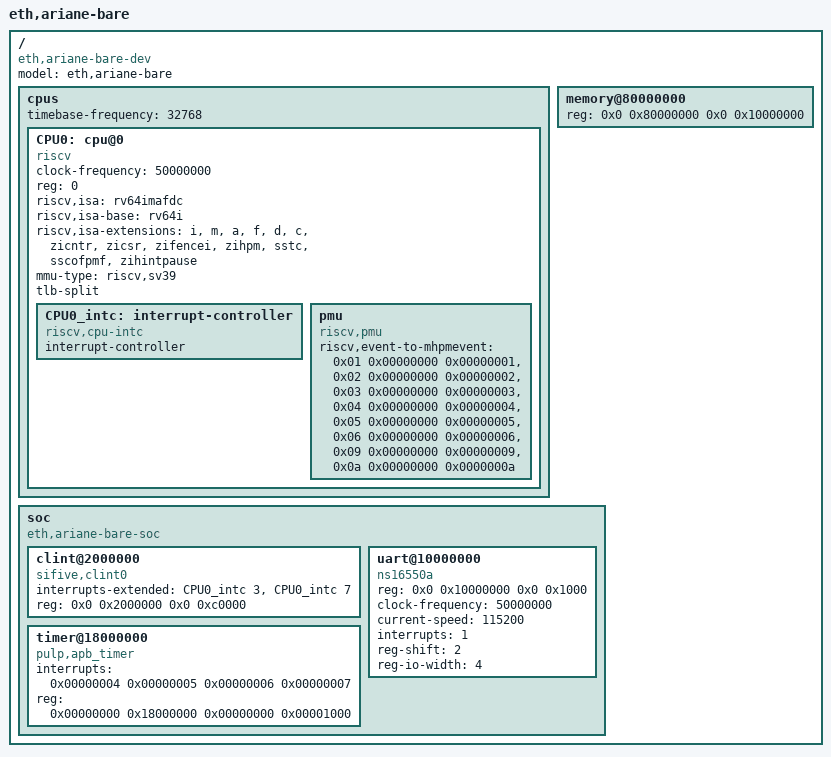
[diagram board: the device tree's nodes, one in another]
/dts-v1/;

/ {
  #address-cells = <2>;
  #size-cells = <2>;
  compatible = "eth,ariane-bare-dev";
  model = "eth,ariane-bare";
  cpus {
    #address-cells = <1>;
    #size-cells = <0>;
    timebase-frequency = <32768>; // 32.768 kHz
    // See AGENTS-dts-validation.md + architecture/multi-threading/dts-linux-smt.md
    // Validated against build-platform/workspace/linux-dts (fetch-linux-dts.ps1).
    // Tandem bare DTS: PLIC remains commented (Unfixable for tandem vs Linux).
    CPU0: cpu@0 {
      clock-frequency = <50000000>; // 50 MHz
      device_type = "cpu";
      reg = <0>;
      status = "okay";
      // Linux cpus.yaml enum does not list eth,ariane — use "riscv" for schema.
      // (Legacy "eth, ariane" was invalid: space + not in binding enum.)
      compatible = "riscv";
      riscv,isa = "rv64imafdc";
      riscv,isa-base = "rv64i";
      // Baseline letter extensions + zic* (fu540-c000.dtsi style) + U7a package extras.
      riscv,isa-extensions = "i", "m", "a", "f", "d", "c",
        "zicntr", "zicsr", "zifencei", "zihpm",
        "sstc", "sscofpmf", "zihintpause";
      mmu-type = "riscv,sv39";
      tlb-split;
      // HLIC - hart local interrupt controller
      CPU0_intc: interrupt-controller {
        #interrupt-cells = <1>;
        interrupt-controller;
        compatible = "riscv,cpu-intc";
      };
      // Sscofpmf / U8a: Linux perf PMU mapping. Event codes match the group-0
      // legacy encoding in core/perf_counters.sv (mhpmeventN low 5 bits).
      pmu {
        compatible = "riscv,pmu";
        riscv,event-to-mhpmevent =
          <0x01 0x00000000 0x00000001>,  /* L1 I-cache miss */
          <0x02 0x00000000 0x00000002>,  /* L1 D-cache miss */
          <0x03 0x00000000 0x00000003>,  /* ITLB miss */
          <0x04 0x00000000 0x00000004>,  /* DTLB miss */
          <0x05 0x00000000 0x00000005>,  /* Load */
          <0x06 0x00000000 0x00000006>,  /* Store */
          <0x09 0x00000000 0x00000009>,  /* Branch */
          <0x0a 0x00000000 0x0000000a>;  /* Branch mispredict */
      };
    };
  };
  memory@80000000 {
    device_type = "memory";
    reg = <0x0 0x80000000 0x0 0x10000000>;
  };
  soc {
    #address-cells = <2>;
    #size-cells = <2>;
    compatible = "eth,ariane-bare-soc", "simple-bus";
    ranges;
    clint@2000000 {
      // sifive,clint.yaml: prefer chip/IP pair; bare riscv,clint0 is deprecated/QEMU-only
      compatible = "sifive,clint0", "riscv,clint0";
      interrupts-extended = <&CPU0_intc 3>, <&CPU0_intc 7>;
      reg = <0x0 0x2000000 0x0 0xc0000>;
    };
    // PLIC needs to be disabled for tandem verification
    // PLIC0: interrupt-controller@c000000 {
    //   #address-cells = <0>;
    //   #interrupt-cells = <1>;
    //   compatible = "sifive,plic-1.0.0", "riscv,plic0";
    //   interrupt-controller;
    //   interrupts-extended = <&CPU0_intc 11 &CPU0_intc 9>;
    //   reg = <0x0 0xc000000 0x0 0x4000000>;
    //   riscv,max-priority = <7>;
    //   riscv,ndev = <2>;
    // };
    // Specifying the interrupt controller in the devicetree is not necessary.
    // Furthermore, the IRQ 65535 will cause a `hwirq 0xffff is too large` during
    // Linux boot (occurred with mainline linux 5.14.0).
    // debug-controller@0 {
    //   compatible = "riscv,debug-013";
    //   interrupts-extended = <&CPU0_intc 65535>;
    //   reg = <0x0 0x0 0x0 0x1000>;
    //   reg-names = "control";
    // };
    uart@10000000 {
      compatible = "ns16550a";
      reg = <0x0 0x10000000 0x0 0x1000>;
      clock-frequency = <50000000>;
      current-speed = <115200>;
      // interrupt-parent = <&PLIC0>;
      interrupts = <1>;
      reg-shift = <2>; // regs are spaced on 32 bit boundary
      reg-io-width = <4>; // only 32-bit access are supported
    };
    timer@18000000 {
      compatible = "pulp,apb_timer";
      interrupts = <0x00000004 0x00000005 0x00000006 0x00000007>;
      reg = <0x00000000 0x18000000 0x00000000 0x00001000>;
      // interrupt-parent = <&PLIC0>;
      reg-names = "control";
    };
  };
};
